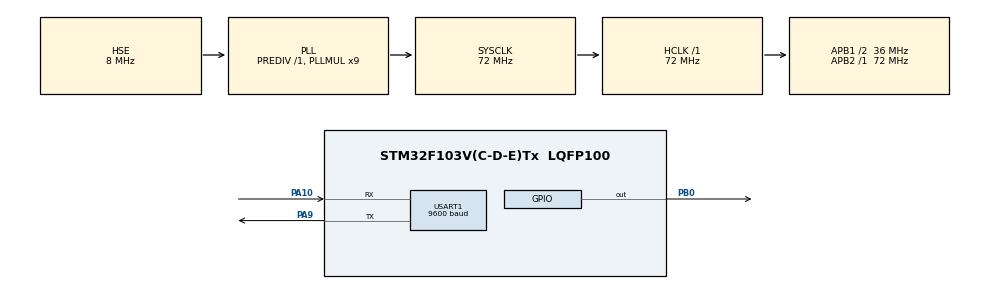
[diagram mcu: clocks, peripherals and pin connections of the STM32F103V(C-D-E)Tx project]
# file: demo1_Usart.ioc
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Dma.Request0=USART1_RX
Dma.USART1_RX.0.Direction=DMA_PERIPH_TO_MEMORY
Dma.USART1_RX.0.Instance=DMA1_Channel5
Dma.USART1_RX.0.MemDataAlignment=DMA_MDATAALIGN_BYTE
Dma.USART1_RX.0.MemInc=DMA_MINC_ENABLE
Dma.USART1_RX.0.Mode=DMA_NORMAL
Dma.USART1_RX.0.PeriphDataAlignment=DMA_PDATAALIGN_BYTE
Dma.USART1_RX.0.PeriphInc=DMA_PINC_DISABLE
Dma.USART1_RX.0.Priority=DMA_PRIORITY_LOW
Mcu.Family=STM32F1
Mcu.Name=STM32F103V(C-D-E)Tx
Mcu.Package=LQFP100
NVIC.DMA1_Channel5_IRQn=true\:0\:0\:false\:false\:true\:false\:true\:true
NVIC.PriorityGroup=NVIC_PRIORITYGROUP_1
NVIC.RCC_IRQn=true\:0\:0\:false\:false\:true\:true\:false\:true
NVIC.USART1_IRQn=true\:0\:0\:false\:false\:true\:true\:true\:true
OSC_IN.Mode=HSE-External-Oscillator
OSC_IN.Signal=RCC_OSC_IN
OSC_OUT.Mode=HSE-External-Oscillator
OSC_OUT.Signal=RCC_OSC_OUT
PA10.Mode=Asynchronous
PA10.Signal=USART1_RX
PA13.Mode=JTAG_5_pins
PA13.Signal=SYS_JTMS-SWDIO
PA14.Mode=JTAG_5_pins
PA14.Signal=SYS_JTCK-SWCLK
PA15.Mode=JTAG_5_pins
PA15.Signal=SYS_JTDI
PA9.Mode=Asynchronous
PA9.Signal=USART1_TX
PB0.Signal=GPIO_Output
PB3.Mode=JTAG_5_pins
PB3.Signal=SYS_JTDO-TRACESWO
PB4.Mode=JTAG_5_pins
PB4.Signal=SYS_NJTRST
ProjectManager.HeapSize=0x200
ProjectManager.StackSize=0x400
ProjectManager.TargetToolchain=MDK-ARM V5.32
RCC.ADCPresc=RCC_ADCPCLK2_DIV6
RCC.AHBFreq_Value=72000000
RCC.APB1CLKDivider=RCC_HCLK_DIV2
RCC.APB1Freq_Value=36000000
RCC.APB1TimFreq_Value=72000000
RCC.APB2Freq_Value=72000000
RCC.APB2TimFreq_Value=72000000
RCC.HCLKFreq_Value=72000000
RCC.PLLMUL=RCC_PLL_MUL9
RCC.PLLSourceVirtual=RCC_PLLSOURCE_HSE
RCC.SYSCLKFreq_VALUE=72000000
RCC.SYSCLKSource=RCC_SYSCLKSOURCE_PLLCLK
RCC.USBFreq_Value=72000000
USART1.BaudRate=9600
USART1.VirtualMode=VM_ASYNC
board=custom

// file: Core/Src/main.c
/* USER CODE BEGIN Header */
/* USER CODE END Header */
#include "main.h"
#include "dma.h"
#include "usart.h"
#include "gpio.h"

/* USER CODE BEGIN Includes */
#include <stdio.h>
#include "cmsis_os.h"
/* USER CODE END Includes */

void SystemClock_Config(void);

/* USER CODE BEGIN 0 */

extern uint32_t os_time;
uint32_t HAL_GetTick(void){
  return os_time;
}

extern uint32_t ADC1_Value[10];   //ADC数据存放数组

uint8_t RX_buff[512]={0};   //定义数据存放数组
uint8_t ch;                 //定义接收缓冲
volatile int flag = 1;               //定义标志�??
int i = 0;                  //定义计数变量

/* USER CODE END 0 */

int main(void)
{

  /* MCU Configuration--------------------------------------------------------*/

  /* Reset of all peripherals, Initializes the Flash interface and the Systick. */
  HAL_Init();

  /* Configure the system clock */
  SystemClock_Config();

  /* Initialize all configured peripherals */
  MX_GPIO_Init();
  MX_DMA_Init();
  MX_USART1_UART_Init();
  /* USER CODE BEGIN 2 */

	HAL_UART_Receive_IT(&huart1,&ch,1);   //�??启中�??

  /* USER CODE END 2 */

  /* Infinite loop */
	while(1)
	{

    /* USER CODE BEGIN 3 */
		//LED_Pwm_Adc();

		if(flag != 0)
		{
      printf("%s",RX_buff);   //串口打印接收到的数据
      flag = 0;               //清空标志�??
    }

		//HAL_Delay(1000);   //延时1s

	}
  /* USER CODE END 3 */
}

void SystemClock_Config(void)
{
  RCC_OscInitTypeDef RCC_OscInitStruct = {0};
  RCC_ClkInitTypeDef RCC_ClkInitStruct = {0};

  /** Initializes the RCC Oscillators according to the specified parameters
  * in the RCC_OscInitTypeDef structure.
  */
  RCC_OscInitStruct.OscillatorType = RCC_OSCILLATORTYPE_HSE;
  RCC_OscInitStruct.HSEState = RCC_HSE_ON;
  RCC_OscInitStruct.HSEPredivValue = RCC_HSE_PREDIV_DIV1;
  RCC_OscInitStruct.HSIState = RCC_HSI_ON;
  RCC_OscInitStruct.PLL.PLLState = RCC_PLL_ON;
  RCC_OscInitStruct.PLL.PLLSource = RCC_PLLSOURCE_HSE;
  RCC_OscInitStruct.PLL.PLLMUL = RCC_PLL_MUL9;
  if (HAL_RCC_OscConfig(&RCC_OscInitStruct) != HAL_OK)
  {
    Error_Handler();
  }

  /** Initializes the CPU, AHB and APB buses clocks
  */
  RCC_ClkInitStruct.ClockType = RCC_CLOCKTYPE_HCLK|RCC_CLOCKTYPE_SYSCLK
                              |RCC_CLOCKTYPE_PCLK1|RCC_CLOCKTYPE_PCLK2;
  RCC_ClkInitStruct.SYSCLKSource = RCC_SYSCLKSOURCE_PLLCLK;
  RCC_ClkInitStruct.AHBCLKDivider = RCC_SYSCLK_DIV1;
  RCC_ClkInitStruct.APB1CLKDivider = RCC_HCLK_DIV2;
  RCC_ClkInitStruct.APB2CLKDivider = RCC_HCLK_DIV1;

  if (HAL_RCC_ClockConfig(&RCC_ClkInitStruct, FLASH_LATENCY_2) != HAL_OK)
  {
    Error_Handler();
  }
}

/* USER CODE BEGIN 4 */

void HAL_UART_RxCpltCallback(UART_HandleTypeDef *huart)
{
  if(huart == &huart1)
	{       //判断是否是串口一的中�??
    RX_buff[i] = ch;          //把写入串口接收的数据
    i++;
    if(ch == 0x0d)//判断结束符（0x0d 回车�??0x0a 换行符）
		{
      for(int t=i;t<512;t++)
			{
        RX_buff[t] = 0;
      }   //清空除接收数据外的数据，防止接收长数据后再次接收短数据出现问�??
      i=0;
      flag = 1;   //接收完成标志
    }
    HAL_UART_Receive_IT(&huart1,&ch,1); //再次�??启中�??
  }
}

/* USER CODE END 4 */

void Error_Handler(void)
{
}
